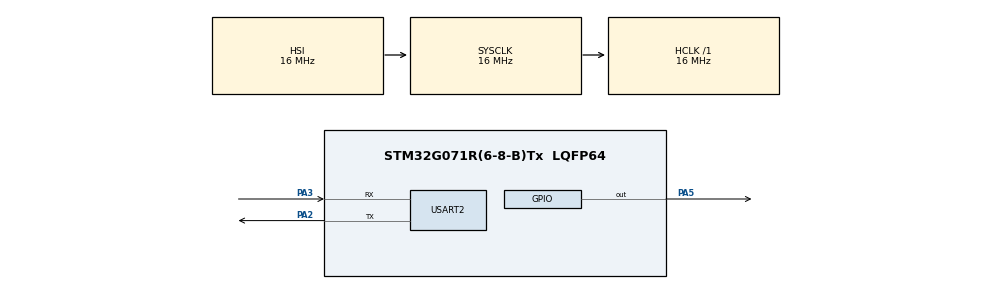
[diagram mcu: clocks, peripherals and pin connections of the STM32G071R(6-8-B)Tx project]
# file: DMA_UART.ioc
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Dma.Request0=USART2_RX
Dma.Request1=USART2_TX
Dma.USART2_RX.0.Direction=DMA_PERIPH_TO_MEMORY
Dma.USART2_RX.0.EventEnable=DISABLE
Dma.USART2_RX.0.Instance=DMA1_Channel6
Dma.USART2_RX.0.MemDataAlignment=DMA_MDATAALIGN_BYTE
Dma.USART2_RX.0.MemInc=DMA_MINC_ENABLE
Dma.USART2_RX.0.Mode=DMA_CIRCULAR
Dma.USART2_RX.0.PeriphDataAlignment=DMA_PDATAALIGN_BYTE
Dma.USART2_RX.0.PeriphInc=DMA_PINC_DISABLE
Dma.USART2_RX.0.Polarity=HAL_DMAMUX_REQ_GEN_RISING
Dma.USART2_RX.0.Priority=DMA_PRIORITY_LOW
Dma.USART2_RX.0.RequestNumber=1
Dma.USART2_RX.0.SignalID=NONE
Dma.USART2_RX.0.SyncEnable=DISABLE
Dma.USART2_RX.0.SyncPolarity=HAL_DMAMUX_SYNC_NO_EVENT
Dma.USART2_RX.0.SyncRequestNumber=1
Dma.USART2_RX.0.SyncSignalID=NONE
Dma.USART2_TX.1.Direction=DMA_MEMORY_TO_PERIPH
Dma.USART2_TX.1.EventEnable=DISABLE
Dma.USART2_TX.1.Instance=DMA1_Channel7
Dma.USART2_TX.1.MemDataAlignment=DMA_MDATAALIGN_BYTE
Dma.USART2_TX.1.MemInc=DMA_MINC_ENABLE
Dma.USART2_TX.1.Mode=DMA_NORMAL
Dma.USART2_TX.1.PeriphDataAlignment=DMA_PDATAALIGN_BYTE
Dma.USART2_TX.1.PeriphInc=DMA_PINC_DISABLE
Dma.USART2_TX.1.Polarity=HAL_DMAMUX_REQ_GEN_RISING
Dma.USART2_TX.1.Priority=DMA_PRIORITY_LOW
Dma.USART2_TX.1.RequestNumber=1
Dma.USART2_TX.1.SignalID=NONE
Dma.USART2_TX.1.SyncEnable=DISABLE
Dma.USART2_TX.1.SyncPolarity=HAL_DMAMUX_SYNC_NO_EVENT
Dma.USART2_TX.1.SyncRequestNumber=1
Dma.USART2_TX.1.SyncSignalID=NONE
Mcu.Family=STM32G0
Mcu.Name=STM32G071R(6-8-B)Tx
Mcu.Package=LQFP64
NVIC.DMA1_Ch4_7_DMAMUX1_OVR_IRQn=true\:0\:0\:false\:false\:true\:false\:true\:true
NVIC.USART2_IRQn=true\:0\:0\:false\:false\:true\:true\:true\:true
PA13.Mode=Serial_Wire
PA13.Signal=SYS_SWDIO
PA14-BOOT0.Mode=Serial_Wire
PA14-BOOT0.Signal=SYS_SWCLK
PA2.Mode=Asynchronous
PA2.Signal=USART2_TX
PA3.Mode=Asynchronous
PA3.Signal=USART2_RX
PA5.Signal=GPIO_Output
ProjectManager.HeapSize=0x200
ProjectManager.StackSize=0x400
ProjectManager.TargetToolchain=STM32CubeIDE
RCC.AHBFreq_Value=16000000
RCC.CortexFreq_Value=16000000
RCC.EXTERNAL_CLOCK_VALUE=48000
RCC.HCLKFreq_Value=16000000
RCC.HSE_VALUE=8000000
RCC.HSI_VALUE=16000000
RCC.LSE_VALUE=32768
RCC.SYSCLKFreq_VALUE=16000000
RCC.VCOOutputFreq_Value=128000000
USART2.VirtualMode-Asynchronous=VM_ASYNC
board=custom

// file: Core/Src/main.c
/* USER CODE BEGIN Header */
/**
  ******************************************************************************
  * @file           : main.c
  * @brief          : Main program body
  ******************************************************************************
  * @attention
  *
  * Copyright (c) 2024 STMicroelectronics.
  * All rights reserved.
  *
  * This software is licensed under terms that can be found in the LICENSE file
  * in the root directory of this software component.
  * If no LICENSE file comes with this software, it is provided AS-IS.
  *
  ******************************************************************************
  */
/* USER CODE END Header */
#include "main.h"

UART_HandleTypeDef huart2;
DMA_HandleTypeDef hdma_usart2_rx;
DMA_HandleTypeDef hdma_usart2_tx;

/* USER CODE BEGIN PV */
char command[] = "Command recieved\r\n";
char buff[1] = "0";
/* USER CODE END PV */

void SystemClock_Config(void);
static void MX_GPIO_Init(void);
static void MX_DMA_Init(void);
static void MX_USART2_UART_Init(void);

int main(void)
{

  /* MCU Configuration--------------------------------------------------------*/

  /* Reset of all peripherals, Initializes the Flash interface and the Systick. */
  HAL_Init();

  /* Configure the system clock */
  SystemClock_Config();

  /* Initialize all configured peripherals */
  MX_GPIO_Init();
  MX_DMA_Init();
  MX_USART2_UART_Init();
  /* USER CODE BEGIN 2 */
  HAL_UART_Receive_DMA(&huart2, &buff, 1);
  /* USER CODE END 2 */

  /* Infinite loop */
  while (1)
  {

  }
}

void SystemClock_Config(void)
{
  RCC_OscInitTypeDef RCC_OscInitStruct = {0};
  RCC_ClkInitTypeDef RCC_ClkInitStruct = {0};

  /** Configure the main internal regulator output voltage
  */
  HAL_PWREx_ControlVoltageScaling(PWR_REGULATOR_VOLTAGE_SCALE1);

  /** Initializes the RCC Oscillators according to the specified parameters
  * in the RCC_OscInitTypeDef structure.
  */
  RCC_OscInitStruct.OscillatorType = RCC_OSCILLATORTYPE_HSI;
  RCC_OscInitStruct.HSIState = RCC_HSI_ON;
  RCC_OscInitStruct.HSIDiv = RCC_HSI_DIV1;
  RCC_OscInitStruct.HSICalibrationValue = RCC_HSICALIBRATION_DEFAULT;
  RCC_OscInitStruct.PLL.PLLState = RCC_PLL_NONE;
  if (HAL_RCC_OscConfig(&RCC_OscInitStruct) != HAL_OK)
  {
    Error_Handler();
  }

  /** Initializes the CPU, AHB and APB buses clocks
  */
  RCC_ClkInitStruct.ClockType = RCC_CLOCKTYPE_HCLK|RCC_CLOCKTYPE_SYSCLK
                              |RCC_CLOCKTYPE_PCLK1;
  RCC_ClkInitStruct.SYSCLKSource = RCC_SYSCLKSOURCE_HSI;
  RCC_ClkInitStruct.AHBCLKDivider = RCC_SYSCLK_DIV1;
  RCC_ClkInitStruct.APB1CLKDivider = RCC_HCLK_DIV1;

  if (HAL_RCC_ClockConfig(&RCC_ClkInitStruct, FLASH_LATENCY_0) != HAL_OK)
  {
    Error_Handler();
  }
}

static void MX_USART2_UART_Init(void)
{

  huart2.Instance = USART2;
  huart2.Init.BaudRate = 115200;
  huart2.Init.WordLength = UART_WORDLENGTH_8B;
  huart2.Init.StopBits = UART_STOPBITS_1;
  huart2.Init.Parity = UART_PARITY_NONE;
  huart2.Init.Mode = UART_MODE_TX_RX;
  huart2.Init.HwFlowCtl = UART_HWCONTROL_NONE;
  huart2.Init.OverSampling = UART_OVERSAMPLING_16;
  huart2.Init.OneBitSampling = UART_ONE_BIT_SAMPLE_DISABLE;
  huart2.Init.ClockPrescaler = UART_PRESCALER_DIV1;
  huart2.AdvancedInit.AdvFeatureInit = UART_ADVFEATURE_NO_INIT;
  if (HAL_UART_Init(&huart2) != HAL_OK)
  {
    Error_Handler();
  }
  if (HAL_UARTEx_SetTxFifoThreshold(&huart2, UART_TXFIFO_THRESHOLD_1_8) != HAL_OK)
  {
    Error_Handler();
  }
  if (HAL_UARTEx_SetRxFifoThreshold(&huart2, UART_RXFIFO_THRESHOLD_1_8) != HAL_OK)
  {
    Error_Handler();
  }
  if (HAL_UARTEx_DisableFifoMode(&huart2) != HAL_OK)
  {
    Error_Handler();
  }

}

static void MX_DMA_Init(void)
{

  /* DMA controller clock enable */
  __HAL_RCC_DMA1_CLK_ENABLE();

  /* DMA interrupt init */
  /* DMA1_Ch4_7_DMAMUX1_OVR_IRQn interrupt configuration */
  HAL_NVIC_SetPriority(DMA1_Ch4_7_DMAMUX1_OVR_IRQn, 0, 0);
  HAL_NVIC_EnableIRQ(DMA1_Ch4_7_DMAMUX1_OVR_IRQn);

}

static void MX_GPIO_Init(void)
{
  GPIO_InitTypeDef GPIO_InitStruct = {0};

  /* GPIO Ports Clock Enable */
  __HAL_RCC_GPIOA_CLK_ENABLE();

  /*Configure GPIO pin Output Level */
  HAL_GPIO_WritePin(GPIOA, GPIO_PIN_5, GPIO_PIN_RESET);

  /*Configure GPIO pin : PA5 */
  GPIO_InitStruct.Pin = GPIO_PIN_5;
  GPIO_InitStruct.Mode = GPIO_MODE_OUTPUT_PP;
  GPIO_InitStruct.Pull = GPIO_NOPULL;
  GPIO_InitStruct.Speed = GPIO_SPEED_FREQ_LOW;
  HAL_GPIO_Init(GPIOA, &GPIO_InitStruct);

}

/* USER CODE BEGIN 4 */
void HAL_UART_RxCpltCallback(UART_HandleTypeDef *huart)
{
  /* Prevent unused argument(s) compilation warning */
  UNUSED(huart);

  /* NOTE : This function should not be modified, when the callback is needed,
            the HAL_UART_RxCpltCallback can be implemented in the user file.
   */
  if(huart->Instance == USART2)
  {
	  if((uint8_t)buff[0] == (uint8_t)'1')
	  {
		  HAL_GPIO_WritePin(GPIOA, GPIO_PIN_5, GPIO_PIN_SET);
	  }
	  else if((uint8_t)buff[0] == (uint8_t)'0')
	  {
		  HAL_GPIO_WritePin(GPIOA, GPIO_PIN_5, GPIO_PIN_RESET);
	  }
	  HAL_UART_Transmit(&huart2, (uint8_t*)command, sizeof(command)/sizeof(char), 10);

  }
}

/* USER CODE END 4 */

void Error_Handler(void)
{
  __disable_irq();
  while (1)
  {
  }
}
